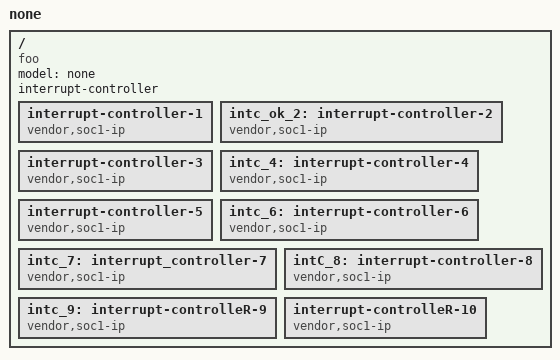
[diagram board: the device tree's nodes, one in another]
// SPDX-License-Identifier: BSD-2-Clause
/dts-v1/;
/ {
	model = "none";
	compatible = "foo";

	#address-cells = <1>;
	#size-cells = <1>;

	interrupt-controller;
	#interrupt-cells = <1>;

	// OK:
	interrupt-controller-1 {
		compatible = "vendor,soc1-ip";
	};

	intc_ok_2: interrupt-controller-2 {
		compatible = "vendor,soc1-ip";
	};

	// ERRORS:
	interrupt-controller-3  {
		compatible = "vendor,soc1-ip";
	};

	intc_4: interrupt-controller-4  {
		compatible = "vendor,soc1-ip";
	};

	intc-5: interrupt-controller-5  {
		compatible = "vendor,soc1-ip";
	};

	intc_6:  interrupt-controller-6 {
		compatible = "vendor,soc1-ip";
	};

	intc_7:interrupt_controller-7 {
		compatible = "vendor,soc1-ip";
	};

	intC_8: interrupt-controller-8 {
		compatible = "vendor,soc1-ip";
	};

	intc_9: interrupt-controlleR-9 {
		compatible = "vendor,soc1-ip";
	};

	interrupt-controlleR-10 {
		compatible = "vendor,soc1-ip";
	};
};
